# CLK2_IVA_BW_REGULATOR register map
Vendor: Texas Instruments
Peripheral module from a debugger description file (folder omap5430_ES2_PUBLIC).
Registers are 32-bit, read-only, reset values left out (the file's numbers can be read two ways) unless marked. A register's access mark holds for its fields unless they carry their own. Offsets are as the file gives them; lines under a group give offsets from that group; [hi:lo] are bit positions; {n}, {i} and the like mark numbered series; 'fields as' and 'values as' point back to an identical list; <NAME> marks a mode.

## CLK2_IVA_BW_REGULATOR
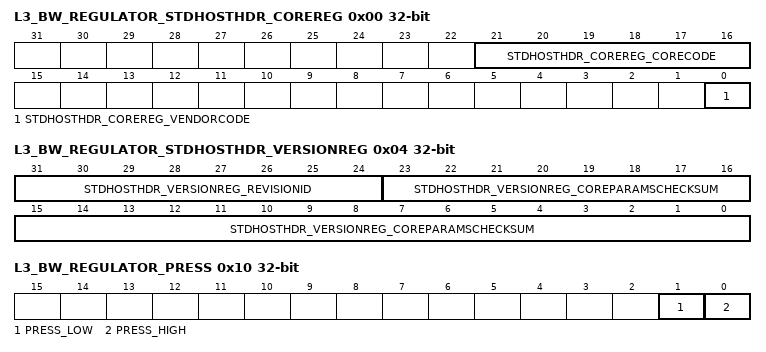
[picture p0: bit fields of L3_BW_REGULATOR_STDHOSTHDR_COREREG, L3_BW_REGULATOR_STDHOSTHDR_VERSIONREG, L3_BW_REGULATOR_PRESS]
0x00 L3_BW_REGULATOR_STDHOSTHDR_COREREG
  [21:16] STDHOSTHDR_COREREG_CORECODE — The Core Code field is a constant reporting a vendor-specific core generator code. Type: Constant. Reset value: 0x31.
  [0] STDHOSTHDR_COREREG_VENDORCODE — The Vendor Code field is a constant reporting the core generator vendor code. Type: Constant. Reset value: 0x1.
    0=Third-party_vendor; 1=STDHOSTHDR_COREREG_VENDORCODE_1_r
0x04 L3_BW_REGULATOR_STDHOSTHDR_VERSIONREG
  [31:24] STDHOSTHDR_VERSIONREG_REVISIONID — The Revision Identifier field is a constant reporting the core generator revision number. Type: Constant. Reset value: 0x0.
  [23:0] STDHOSTHDR_VERSIONREG_COREPARAMSCHECKSUM — Reserved. Type: Reserved. Reset value: Reserved.
0x08 L3_BW_REGULATOR_BANDWIDTH access per field
  [15:0] BANDWIDTH rw — Bandwidth, in bytes per second. Type: Control. Reset value: 0x0.
0x0C L3_BW_REGULATOR_WATERMARK access per field
  [11:0] WATERMARK rw — Peak permissible bandwidth, in bytes. Type: Control. Reset value: 0x1.
0x10 L3_BW_REGULATOR_PRESS
  [1] PRESS_LOW — Pressure value inserted if the measured bandwidth is over the watermark. The pressure is bar graph encoded. Type: Control. Reset value: 0x0.
  [0] PRESS_HIGH — Pressure value inserted if the measured bandwidth is under the watermark. The pressure is bar graph encoded. Type: Control. Reset value: 0x1.
0x14 L3_BW_REGULATOR_CLEARHISTORY access per field
  [0] CLEARHISTORY rw — Write a 1 clear the traffic counter Type: Give_AutoCleared. Reset value: 0x0.
